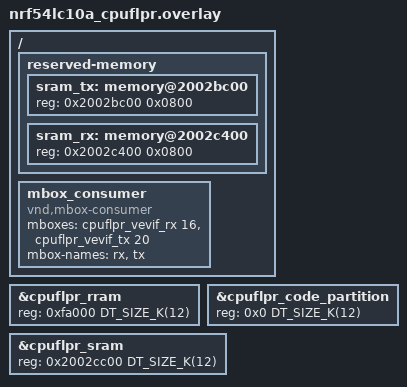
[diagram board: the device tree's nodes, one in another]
/*
 * Copyright (c) 2026 Nordic Semiconductor ASA
 *
 * SPDX-License-Identifier: LicenseRef-Nordic-5-Clause
 */

/ {
	reserved-memory {
		#address-cells = <1>;
		#size-cells = <1>;
		ranges;

		sram_tx: memory@2002bc00 {
			reg = <0x2002bc00 0x0800>;
		};

		sram_rx: memory@2002c400 {
			reg = <0x2002c400 0x0800>;
		};
	};

	mbox_consumer: mbox_consumer {
		compatible = "vnd,mbox-consumer";
		mboxes = <&cpuflpr_vevif_rx 16>, <&cpuflpr_vevif_tx 20>;
		mbox-names = "rx", "tx";
	};
};

&cpuflpr_rram {
	reg = <0xfa000 DT_SIZE_K(12)>;
	ranges = <0x0 0xfa000 DT_SIZE_K(12)>;
	#address-cells = <1>;
	#size-cells = <1>;
};

&cpuflpr_code_partition {
	reg = <0x0 DT_SIZE_K(12)>;
};

&cpuflpr_sram {
	reg = <0x2002cc00 DT_SIZE_K(12)>;
	ranges = <0x0 0x2002cc00 DT_SIZE_K(12)>;
};
